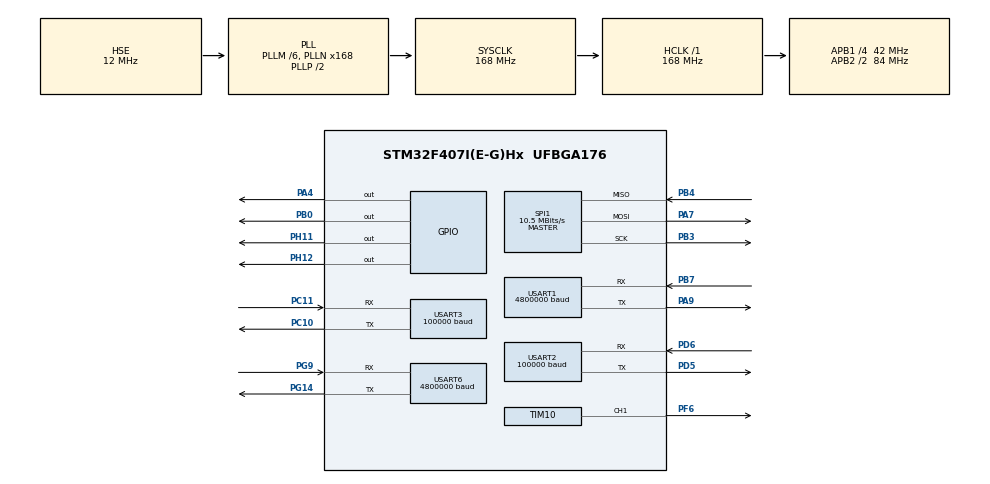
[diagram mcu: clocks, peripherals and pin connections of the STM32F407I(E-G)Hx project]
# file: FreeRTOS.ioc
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Dma.Request0=SPI1_RX
Dma.Request1=SPI1_TX
Dma.Request2=USART1_RX
Dma.Request3=USART1_TX
Dma.Request4=USART3_RX
Dma.Request5=USART6_RX
Dma.Request6=USART6_TX
Dma.Request7=USART2_RX
Dma.Request8=USART2_TX
Dma.SPI1_RX.0.Direction=DMA_PERIPH_TO_MEMORY
Dma.SPI1_RX.0.FIFOMode=DMA_FIFOMODE_DISABLE
Dma.SPI1_RX.0.Instance=DMA2_Stream2
Dma.SPI1_RX.0.MemDataAlignment=DMA_MDATAALIGN_BYTE
Dma.SPI1_RX.0.MemInc=DMA_MINC_ENABLE
Dma.SPI1_RX.0.Mode=DMA_NORMAL
Dma.SPI1_RX.0.PeriphDataAlignment=DMA_PDATAALIGN_BYTE
Dma.SPI1_RX.0.PeriphInc=DMA_PINC_DISABLE
Dma.SPI1_RX.0.Priority=DMA_PRIORITY_VERY_HIGH
Dma.SPI1_TX.1.Direction=DMA_MEMORY_TO_PERIPH
Dma.SPI1_TX.1.FIFOMode=DMA_FIFOMODE_DISABLE
Dma.SPI1_TX.1.Instance=DMA2_Stream3
Dma.SPI1_TX.1.MemDataAlignment=DMA_MDATAALIGN_BYTE
Dma.SPI1_TX.1.MemInc=DMA_MINC_ENABLE
Dma.SPI1_TX.1.Mode=DMA_NORMAL
Dma.SPI1_TX.1.PeriphDataAlignment=DMA_PDATAALIGN_BYTE
Dma.SPI1_TX.1.PeriphInc=DMA_PINC_DISABLE
Dma.SPI1_TX.1.Priority=DMA_PRIORITY_HIGH
Dma.USART1_RX.2.Direction=DMA_PERIPH_TO_MEMORY
Dma.USART1_RX.2.FIFOMode=DMA_FIFOMODE_DISABLE
Dma.USART1_RX.2.Instance=DMA2_Stream5
Dma.USART1_RX.2.MemDataAlignment=DMA_MDATAALIGN_BYTE
Dma.USART1_RX.2.MemInc=DMA_MINC_ENABLE
Dma.USART1_RX.2.Mode=DMA_NORMAL
Dma.USART1_RX.2.PeriphDataAlignment=DMA_PDATAALIGN_BYTE
Dma.USART1_RX.2.PeriphInc=DMA_PINC_DISABLE
Dma.USART1_RX.2.Priority=DMA_PRIORITY_LOW
Dma.USART1_TX.3.Direction=DMA_MEMORY_TO_PERIPH
Dma.USART1_TX.3.FIFOMode=DMA_FIFOMODE_DISABLE
Dma.USART1_TX.3.Instance=DMA2_Stream7
Dma.USART1_TX.3.MemDataAlignment=DMA_MDATAALIGN_BYTE
Dma.USART1_TX.3.MemInc=DMA_MINC_ENABLE
Dma.USART1_TX.3.Mode=DMA_NORMAL
Dma.USART1_TX.3.PeriphDataAlignment=DMA_PDATAALIGN_BYTE
Dma.USART1_TX.3.PeriphInc=DMA_PINC_DISABLE
Dma.USART1_TX.3.Priority=DMA_PRIORITY_MEDIUM
Dma.USART2_RX.7.Direction=DMA_PERIPH_TO_MEMORY
Dma.USART2_RX.7.FIFOMode=DMA_FIFOMODE_DISABLE
Dma.USART2_RX.7.Instance=DMA1_Stream5
Dma.USART2_RX.7.MemDataAlignment=DMA_MDATAALIGN_BYTE
Dma.USART2_RX.7.MemInc=DMA_MINC_ENABLE
Dma.USART2_RX.7.Mode=DMA_NORMAL
Dma.USART2_RX.7.PeriphDataAlignment=DMA_PDATAALIGN_BYTE
Dma.USART2_RX.7.PeriphInc=DMA_PINC_DISABLE
Dma.USART2_RX.7.Priority=DMA_PRIORITY_LOW
Dma.USART2_TX.8.Direction=DMA_MEMORY_TO_PERIPH
Dma.USART2_TX.8.FIFOMode=DMA_FIFOMODE_DISABLE
Dma.USART2_TX.8.Instance=DMA1_Stream6
Dma.USART2_TX.8.MemDataAlignment=DMA_MDATAALIGN_BYTE
Dma.USART2_TX.8.MemInc=DMA_MINC_ENABLE
Dma.USART2_TX.8.Mode=DMA_NORMAL
Dma.USART2_TX.8.PeriphDataAlignment=DMA_PDATAALIGN_BYTE
Dma.USART2_TX.8.PeriphInc=DMA_PINC_DISABLE
Dma.USART2_TX.8.Priority=DMA_PRIORITY_LOW
Dma.USART3_RX.4.Direction=DMA_PERIPH_TO_MEMORY
Dma.USART3_RX.4.FIFOMode=DMA_FIFOMODE_DISABLE
Dma.USART3_RX.4.Instance=DMA1_Stream1
Dma.USART3_RX.4.MemDataAlignment=DMA_MDATAALIGN_BYTE
Dma.USART3_RX.4.MemInc=DMA_MINC_ENABLE
Dma.USART3_RX.4.Mode=DMA_NORMAL
Dma.USART3_RX.4.PeriphDataAlignment=DMA_PDATAALIGN_BYTE
Dma.USART3_RX.4.PeriphInc=DMA_PINC_DISABLE
Dma.USART3_RX.4.Priority=DMA_PRIORITY_HIGH
Dma.USART6_RX.5.Direction=DMA_PERIPH_TO_MEMORY
Dma.USART6_RX.5.FIFOMode=DMA_FIFOMODE_DISABLE
Dma.USART6_RX.5.Instance=DMA2_Stream1
Dma.USART6_RX.5.MemDataAlignment=DMA_MDATAALIGN_BYTE
Dma.USART6_RX.5.MemInc=DMA_MINC_ENABLE
Dma.USART6_RX.5.Mode=DMA_NORMAL
Dma.USART6_RX.5.PeriphDataAlignment=DMA_PDATAALIGN_BYTE
Dma.USART6_RX.5.PeriphInc=DMA_PINC_DISABLE
Dma.USART6_RX.5.Priority=DMA_PRIORITY_LOW
Dma.USART6_TX.6.Direction=DMA_MEMORY_TO_PERIPH
Dma.USART6_TX.6.FIFOMode=DMA_FIFOMODE_DISABLE
Dma.USART6_TX.6.Instance=DMA2_Stream6
Dma.USART6_TX.6.MemDataAlignment=DMA_MDATAALIGN_BYTE
Dma.USART6_TX.6.MemInc=DMA_MINC_ENABLE
Dma.USART6_TX.6.Mode=DMA_NORMAL
Dma.USART6_TX.6.PeriphDataAlignment=DMA_PDATAALIGN_BYTE
Dma.USART6_TX.6.PeriphInc=DMA_PINC_DISABLE
Dma.USART6_TX.6.Priority=DMA_PRIORITY_MEDIUM
FREERTOS.Tasks01=defaultTask,24,128,StartDefaultTask,Default,NULL,Dynamic,NULL,NULL;START_LEDR_TASK,8,128,StartLEDrTask,Default,NULL,Dynamic,NULL,NULL;START_LEDG_TASK,8,128,StartLEDgTask,Default,NULL,Dynamic,NULL,NULL;START_IMU_TASK,8,1024,StartIMUTask,Default,NULL,Dynamic,NULL,NULL
FREERTOS.configUSE_NEWLIB_REENTRANT=1
Mcu.Family=STM32F4
Mcu.Name=STM32F407I(E-G)Hx
Mcu.Package=UFBGA176
NVIC.DMA1_Stream1_IRQn=true\:5\:0\:false\:false\:true\:true\:false\:true\:true
NVIC.DMA1_Stream5_IRQn=true\:5\:0\:false\:false\:true\:true\:false\:true\:true
NVIC.DMA1_Stream6_IRQn=true\:5\:0\:false\:false\:true\:true\:false\:true\:true
NVIC.DMA2_Stream1_IRQn=true\:5\:0\:false\:false\:true\:true\:false\:true\:true
NVIC.DMA2_Stream2_IRQn=true\:5\:0\:false\:false\:true\:false\:false\:true\:true
NVIC.DMA2_Stream3_IRQn=true\:5\:0\:false\:false\:true\:true\:false\:true\:true
NVIC.DMA2_Stream5_IRQn=true\:5\:0\:false\:false\:true\:true\:false\:true\:true
NVIC.DMA2_Stream6_IRQn=true\:5\:0\:false\:false\:true\:true\:false\:true\:true
NVIC.DMA2_Stream7_IRQn=true\:5\:0\:false\:false\:true\:true\:false\:true\:true
NVIC.PriorityGroup=NVIC_PRIORITYGROUP_4
NVIC.SPI1_IRQn=true\:5\:0\:false\:false\:true\:true\:true\:true\:true
NVIC.TIM7_IRQn=true\:15\:0\:false\:false\:true\:false\:false\:true\:true
NVIC.TimeBase=TIM7_IRQn
NVIC.TimeBaseIP=TIM7
NVIC.USART1_IRQn=true\:5\:0\:false\:false\:true\:true\:true\:true\:true
NVIC.USART2_IRQn=true\:5\:0\:false\:false\:true\:true\:true\:true\:true
NVIC.USART3_IRQn=true\:5\:0\:false\:false\:true\:true\:true\:true\:true
NVIC.USART6_IRQn=true\:5\:0\:false\:false\:true\:true\:true\:true\:true
PA13.Mode=Serial_Wire
PA13.Signal=SYS_JTMS-SWDIO
PA14.Mode=Serial_Wire
PA14.Signal=SYS_JTCK-SWCLK
PA4.PinState=GPIO_PIN_SET
PA4.Signal=GPIO_Output
PA7.GPIO_PuPd=GPIO_PULLUP
PA7.Mode=Full_Duplex_Master
PA7.Signal=SPI1_MOSI
PA9.Mode=Asynchronous
PA9.Signal=USART1_TX
PB0.PinState=GPIO_PIN_SET
PB0.Signal=GPIO_Output
PB3.GPIO_PuPd=GPIO_PULLUP
PB3.Mode=Full_Duplex_Master
PB3.Signal=SPI1_SCK
PB4.GPIO_PuPd=GPIO_PULLUP
PB4.Mode=Full_Duplex_Master
PB4.Signal=SPI1_MISO
PB7.Mode=Asynchronous
PB7.Signal=USART1_RX
PC10.Mode=Asynchronous
PC10.Signal=USART3_TX
PC11.Mode=Asynchronous
PC11.Signal=USART3_RX
PD5.Mode=Asynchronous
PD5.Signal=USART2_TX
PD6.Mode=Asynchronous
PD6.Signal=USART2_RX
PF6.GPIO_PuPd=GPIO_PULLUP
PF6.GPIO_Speed=GPIO_SPEED_FREQ_HIGH
PF6.Signal=S_TIM10_CH1
PG14.Mode=Asynchronous
PG14.Signal=USART6_TX
PG9.Mode=Asynchronous
PG9.Signal=USART6_RX
PH0-OSC_IN.Mode=HSE-External-Oscillator
PH0-OSC_IN.Signal=RCC_OSC_IN
PH1-OSC_OUT.Mode=HSE-External-Oscillator
PH1-OSC_OUT.Signal=RCC_OSC_OUT
PH11.PinState=GPIO_PIN_SET
PH11.Signal=GPIO_Output
PH12.PinState=GPIO_PIN_SET
PH12.Signal=GPIO_Output
ProjectManager.HeapSize=0x200
ProjectManager.StackSize=0x400
ProjectManager.TargetToolchain=STM32CubeIDE
RCC.48MHZClocksFreq_Value=84000000
RCC.AHBFreq_Value=168000000
RCC.APB1CLKDivider=RCC_HCLK_DIV4
RCC.APB1Freq_Value=42000000
RCC.APB1TimFreq_Value=84000000
RCC.APB2CLKDivider=RCC_HCLK_DIV2
RCC.APB2Freq_Value=84000000
RCC.APB2TimFreq_Value=168000000
RCC.CortexFreq_Value=168000000
RCC.HCLKFreq_Value=168000000
RCC.HSE_VALUE=12000000
RCC.HSI_VALUE=16000000
RCC.LSE_VALUE=32768
RCC.PLLM=6
RCC.PLLN=168
RCC.PLLSourceVirtual=RCC_PLLSOURCE_HSE
RCC.SYSCLKFreq_VALUE=168000000
RCC.SYSCLKSource=RCC_SYSCLKSOURCE_PLLCLK
RCC.VCOOutputFreq_Value=336000000
SH.S_TIM10_CH1.0=TIM10_CH1,PWM Generation1 CH1
SPI1.BaudRatePrescaler=SPI_BAUDRATEPRESCALER_8
SPI1.CLKPhase=SPI_PHASE_2EDGE
SPI1.CLKPolarity=SPI_POLARITY_HIGH
SPI1.CalculateBaudRate=10.5 MBits/s
SPI1.Direction=SPI_DIRECTION_2LINES
SPI1.Mode=SPI_MODE_MASTER
SPI1.VirtualType=VM_MASTER
TIM10.Channel=TIM_CHANNEL_1
TIM10.Period=1999
TIM10.Prescaler=83
USART1.BaudRate=4800000
USART1.VirtualMode=VM_ASYNC
USART2.BaudRate=100000
USART2.Parity=PARITY_EVEN
USART2.VirtualMode=VM_ASYNC
USART2.WordLength=WORDLENGTH_9B
USART3.BaudRate=100000
USART3.Parity=PARITY_EVEN
USART3.VirtualMode=VM_ASYNC
USART3.WordLength=WORDLENGTH_9B
USART6.BaudRate=4800000
USART6.VirtualMode=VM_ASYNC
VP_FREERTOS_VS_CMSIS_V2.Mode=CMSIS_V2
VP_SYS_VS_tim7.Mode=TIM7
VP_TIM10_VS_ClockSourceINT.Mode=Enable_Timer
board=custom

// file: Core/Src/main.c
/* USER CODE BEGIN Header */
/**
  ******************************************************************************
  * @file           : main.c
  * @brief          : Main program body
  ******************************************************************************
  * @attention
  *
  * Copyright (c) 2024 STMicroelectronics.
  * All rights reserved.
  *
  * This software is licensed under terms that can be found in the LICENSE file
  * in the root directory of this software component.
  * If no LICENSE file comes with this software, it is provided AS-IS.
  *
  ******************************************************************************
  */
/* USER CODE END Header */
#include "main.h"
#include "cmsis_os.h"
#include "dma.h"
#include "spi.h"
#include "tim.h"
#include "usart.h"
#include "gpio.h"

/* USER CODE BEGIN Includes */
#include "FreeRTOS.h"
#include "bsp_dwt.h"
#include "BMI088driver.h"
/* USER CODE END Includes */

void SystemClock_Config(void);
void MX_FREERTOS_Init(void);

int main(void)
{

  /* MCU Configuration--------------------------------------------------------*/

  /* Reset of all peripherals, Initializes the Flash interface and the Systick. */
  HAL_Init();

  /* Configure the system clock */
  SystemClock_Config();

  /* Initialize all configured peripherals */
  MX_GPIO_Init();
  MX_DMA_Init();
  MX_SPI1_Init();
  MX_TIM10_Init();
  MX_USART1_UART_Init();
  MX_USART3_UART_Init();
  MX_USART6_UART_Init();
  MX_USART2_UART_Init();
  /* USER CODE BEGIN 2 */
  DWT_Init(168);
  while (BMI088_init(&hspi1, 1) != BMI088_NO_ERROR);
  /* USER CODE END 2 */

  /* Init scheduler */
  osKernelInitialize();  /* Call init function for freertos objects (in freertos.c) */
  MX_FREERTOS_Init();

  /* Start scheduler */
  osKernelStart();

  /* We should never get here as control is now taken by the scheduler */
  /* Infinite loop */
  while (1)
  {

  }
}

void SystemClock_Config(void)
{
  RCC_OscInitTypeDef RCC_OscInitStruct = {0};
  RCC_ClkInitTypeDef RCC_ClkInitStruct = {0};

  /** Configure the main internal regulator output voltage
  */
  __HAL_RCC_PWR_CLK_ENABLE();
  __HAL_PWR_VOLTAGESCALING_CONFIG(PWR_REGULATOR_VOLTAGE_SCALE1);

  /** Initializes the RCC Oscillators according to the specified parameters
  * in the RCC_OscInitTypeDef structure.
  */
  RCC_OscInitStruct.OscillatorType = RCC_OSCILLATORTYPE_HSE;
  RCC_OscInitStruct.HSEState = RCC_HSE_ON;
  RCC_OscInitStruct.PLL.PLLState = RCC_PLL_ON;
  RCC_OscInitStruct.PLL.PLLSource = RCC_PLLSOURCE_HSE;
  RCC_OscInitStruct.PLL.PLLM = 6;
  RCC_OscInitStruct.PLL.PLLN = 168;
  RCC_OscInitStruct.PLL.PLLP = RCC_PLLP_DIV2;
  RCC_OscInitStruct.PLL.PLLQ = 4;
  if (HAL_RCC_OscConfig(&RCC_OscInitStruct) != HAL_OK)
  {
    Error_Handler();
  }

  /** Initializes the CPU, AHB and APB buses clocks
  */
  RCC_ClkInitStruct.ClockType = RCC_CLOCKTYPE_HCLK|RCC_CLOCKTYPE_SYSCLK
                              |RCC_CLOCKTYPE_PCLK1|RCC_CLOCKTYPE_PCLK2;
  RCC_ClkInitStruct.SYSCLKSource = RCC_SYSCLKSOURCE_PLLCLK;
  RCC_ClkInitStruct.AHBCLKDivider = RCC_SYSCLK_DIV1;
  RCC_ClkInitStruct.APB1CLKDivider = RCC_HCLK_DIV4;
  RCC_ClkInitStruct.APB2CLKDivider = RCC_HCLK_DIV2;

  if (HAL_RCC_ClockConfig(&RCC_ClkInitStruct, FLASH_LATENCY_5) != HAL_OK)
  {
    Error_Handler();
  }
}

void HAL_TIM_PeriodElapsedCallback(TIM_HandleTypeDef *htim)
{
  if (htim->Instance == TIM7) {
    HAL_IncTick();
  }
}

void Error_Handler(void)
{
  __disable_irq();
  while (1)
  {
  }
}

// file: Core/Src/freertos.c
/* USER CODE BEGIN Header */
/**
  ******************************************************************************
  * File Name          : freertos.c
  * Description        : Code for freertos applications
  ******************************************************************************
  * @attention
  *
  * Copyright (c) 2024 STMicroelectronics.
  * All rights reserved.
  *
  * This software is licensed under terms that can be found in the LICENSE file
  * in the root directory of this software component.
  * If no LICENSE file comes with this software, it is provided AS-IS.
  *
  ******************************************************************************
  */
/* USER CODE END Header */

#include "FreeRTOS.h"
#include "task.h"
#include "main.h"
#include "cmsis_os.h"

/* USER CODE BEGIN Includes */
#include "LEDg_task.h"
#include "LEDr_task.h"
#include "imu_task.h"
/* USER CODE END Includes */

/* Definitions for defaultTask */
osThreadId_t defaultTaskHandle;
const osThreadAttr_t defaultTask_attributes = {
  .name = "defaultTask",
  .stack_size = 128 * 4,
  .priority = (osPriority_t) osPriorityNormal,
};
/* Definitions for START_LEDR_TASK */
osThreadId_t START_LEDR_TASKHandle;
const osThreadAttr_t START_LEDR_TASK_attributes = {
  .name = "START_LEDR_TASK",
  .stack_size = 128 * 4,
  .priority = (osPriority_t) osPriorityLow,
};
/* Definitions for START_LEDG_TASK */
osThreadId_t START_LEDG_TASKHandle;
const osThreadAttr_t START_LEDG_TASK_attributes = {
  .name = "START_LEDG_TASK",
  .stack_size = 128 * 4,
  .priority = (osPriority_t) osPriorityLow,
};
/* Definitions for START_IMU_TASK */
osThreadId_t START_IMU_TASKHandle;
const osThreadAttr_t START_IMU_TASK_attributes = {
  .name = "START_IMU_TASK",
  .stack_size = 1024 * 4,
  .priority = (osPriority_t) osPriorityLow,
};

void StartDefaultTask(void *argument);
void StartLEDrTask(void *argument);
void StartLEDgTask(void *argument);
void StartIMUTask(void *argument);

void MX_FREERTOS_Init(void); /* (MISRA C 2004 rule 8.1) */

void MX_FREERTOS_Init(void) {

  /* Create the thread(s) */
  /* creation of defaultTask */
  defaultTaskHandle = osThreadNew(StartDefaultTask, NULL, &defaultTask_attributes);

  /* creation of START_LEDR_TASK */
  START_LEDR_TASKHandle = osThreadNew(StartLEDrTask, NULL, &START_LEDR_TASK_attributes);

  /* creation of START_LEDG_TASK */
  START_LEDG_TASKHandle = osThreadNew(StartLEDgTask, NULL, &START_LEDG_TASK_attributes);

  /* creation of START_IMU_TASK */
  START_IMU_TASKHandle = osThreadNew(StartIMUTask, NULL, &START_IMU_TASK_attributes);

}

void StartDefaultTask(void *argument)
{
  for(;;)
  {
    osDelay(1);
  }
}

void StartLEDrTask(void *argument)
{
  /* USER CODE BEGIN StartLEDrTask */
  /* Infinite loop */
  for(;;)
  {
    LEDr_Task();
    osDelay(500);
  }
  /* USER CODE END StartLEDrTask */
}

void StartLEDgTask(void *argument)
{
  /* USER CODE BEGIN StartLEDgTask */
  /* Infinite loop */
  for(;;)
  {
    LEDg_Task();
    osDelay(1000);
  }
  /* USER CODE END StartLEDgTask */
}

void StartIMUTask(void *argument)
{
  /* USER CODE BEGIN StartIMUTask */
  IMU_Init();
  /* Infinite loop */
  for(;;)
  {
    IMU_Task();
    osDelay(1);
  }
  /* USER CODE END StartIMUTask */
}
